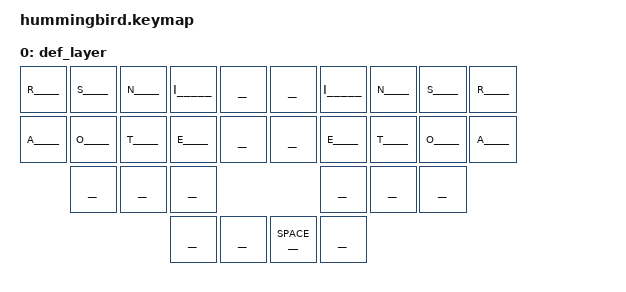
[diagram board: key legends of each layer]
#define HOST_OS 2

#include <behaviors.dtsi>
#include <dt-bindings/zmk/keys.h>
#include <dt-bindings/zmk/bt.h>

#include "./helpers/nodefree.h"
#include "./helpers/keypos_20key.h"
#include "./keycodes.h"

#define DEF 0

/**
 * ----------------------------------------------
 * DEFAULT ALPHA LAYER
 * ----------------------------------------------
 */

ZMK_LAYER(def_layer,
// ╭─────────────┬─────────────┬─────────────┬─────────────┬─────────────╮   ╭─────────────┬─────────────┬─────────────┬─────────────┬─────────────╮
     _____R_____   _____S_____   _____N_____   _____I_____   ___________       ___________   _____I_____   _____N_____   _____S_____   _____R_____
// ├─────────────┼─────────────┼─────────────┼─────────────┼─────────────┤   ├─────────────┼─────────────┼─────────────┼─────────────┼─────────────┤
     _____A_____   _____O_____   _____T_____   _____E_____   ___________       ___________   _____E_____   _____T_____   _____O_____   _____A_____
// ├─────────────┼─────────────┼─────────────┼─────────────┼─────────────┤   ╰─────────────┼─────────────┼─────────────┼─────────────┼─────────────╯
                   ___________   ___________   ___________                                   ___________   ___________   ___________
//               ╰─────────────┼─────────────┼─────────────╯                               ╰─────────────┴─────────────┴─────────────╯
                                               ___________   ___________       ___SPACE___   ___________
//                                           ╰─────────────┴─────────────╯   ╰─────────────┴─────────────╯
)

/**
 * ----------------------------------------------
 * COMBO LEFT UTILITY
 * ----------------------------------------------
 */

ZMK_COMBO(keylTab, ____TAB____, LT0 LT1 LT2, DEF, 130)
ZMK_COMBO(keylEnt, ___ENTER___, LB0 LB1 LB2, DEF, 130)
ZMK_COMBO(keylBsp, ___BKSPC___, LB1 LB2 LB3, DEF, 130)
ZMK_COMBO(keylEsc, ____ESC____, LT1 LT2 LT3, DEF, 130)

/**
 * ----------------------------------------------
 * COMBO RIGHT UTILITY
 * ----------------------------------------------
 */

ZMK_COMBO(keyrTab, ____TAB____, RT0 RT1 RT2, DEF, 130)
ZMK_COMBO(keyrEnt, ___ENTER___, RB0 RB1 RB2, DEF, 130)
ZMK_COMBO(keyrBsp, ___BKSPC___, RB1 RB2 RB3, DEF, 130)
ZMK_COMBO(keyrEsc, ____ESC____, RT1 RT2 RT3, DEF, 130)

/**
 * ----------------------------------------------
 * COMBO LEFT LOWER ALPHAS
 * ----------------------------------------------
 */

ZMK_COMBO(keylb, &kp B, LT3 LT2, DEF, 30)
ZMK_COMBO(keyly, &kp Y, LT1 LT0, DEF, 30)
ZMK_COMBO(keyll, &kp L, LB3 LB2, DEF, 30)
ZMK_COMBO(keylh, &kp H, LB1 LB0, DEF, 30)
ZMK_COMBO(keylu, &kp U, LB2 LB1, DEF, 30)
ZMK_COMBO(keylp, &kp P, LT2 LT1, DEF, 30)
ZMK_COMBO(keyld, &kp D, LB3 LB0, DEF, 30)
ZMK_COMBO(keylg, &kp G, LT3 LT0, DEF, 30)
ZMK_COMBO(keylz, &kp Z, LT3 LT1, DEF, 30)
ZMK_COMBO(keylf, &kp F, LT2 LT0, DEF, 30)
ZMK_COMBO(keylq, &kp Q, LB3 LB1, DEF, 30)
ZMK_COMBO(keylc, &kp C, LB2 LB0, DEF, 30)
ZMK_COMBO(keylx, &kp X, LT3 LB1, DEF, 30)
ZMK_COMBO(keylk, &kp K, LB2 LT0, DEF, 30)
ZMK_COMBO(keylv, &kp V, LT2 LB0, DEF, 30)
ZMK_COMBO(keylj, &kp J, LB3 LT1, DEF, 30)
ZMK_COMBO(keylm, &kp M, LT3 LB0, DEF, 30)
ZMK_COMBO(keylw, &kp W, LB3 LT0, DEF, 30)

/**
 * ----------------------------------------------
 * COMBO RIGHT LOWER ALPHAS
 * ----------------------------------------------
 */

ZMK_COMBO(keyrb, &kp B, RT3 RT2, DEF, 30)
ZMK_COMBO(keyry, &kp Y, RT1 RT0, DEF, 30)
ZMK_COMBO(keyrl, &kp L, RB3 RB2, DEF, 30)
ZMK_COMBO(keyrh, &kp H, RB1 RB0, DEF, 30)
ZMK_COMBO(keyru, &kp U, RB2 RB1, DEF, 30)
ZMK_COMBO(keyrp, &kp P, RT2 RT1, DEF, 30)
ZMK_COMBO(keyrd, &kp D, RB3 RB0, DEF, 30)
ZMK_COMBO(keyrg, &kp G, RT3 RT0, DEF, 30)
ZMK_COMBO(keyrz, &kp Z, RT3 RT1, DEF, 30)
ZMK_COMBO(keyrf, &kp F, RT2 RT0, DEF, 30)
ZMK_COMBO(keyrq, &kp Q, RB3 RB1, DEF, 30)
ZMK_COMBO(keyrc, &kp C, RB2 RB0, DEF, 30)
ZMK_COMBO(keyrx, &kp X, RT3 RB1, DEF, 30)
ZMK_COMBO(keyrk, &kp K, RB2 RT0, DEF, 30)
ZMK_COMBO(keyrv, &kp V, RT2 RB0, DEF, 30)
ZMK_COMBO(keyrj, &kp J, RB3 RT1, DEF, 30)
ZMK_COMBO(keyrm, &kp M, RT3 RB0, DEF, 30)
ZMK_COMBO(keyrw, &kp W, RB3 RT0, DEF, 30)
